VERSION ""

NS_ :

BS_:

BU_: HCU BMS MCU

BO_ 3221225472 VECTOR__INDEPENDENT_SIG_MSG: 0 Vector__XXX
 SG_ SI_30Bit : 0|30@1- (1,0) [0|0] "" Vector__XXX
 SG_ SI_29Bit : 0|29@1- (1,0) [0|0] "" Vector__XXX
 SG_ SI_28Bit : 0|28@1- (1,0) [0|0] "" Vector__XXX
 SG_ SI_27Bit : 0|27@1- (1,0) [0|0] "" Vector__XXX
 SG_ SI_26Bit : 0|26@1- (1,0) [0|0] "" Vector__XXX
 SG_ SI_25Bit : 0|25@1- (1,0) [0|0] "" Vector__XXX
 SG_ SI_23Bit : 0|23@1- (1,0) [0|0] "" Vector__XXX
 SG_ SI_22Bit : 0|22@1- (1,0) [0|0] "" Vector__XXX
 SG_ SI_21Bit : 0|21@1- (1,0) [0|0] "" Vector__XXX
 SG_ SI_20Bit : 0|20@1- (1,0) [0|0] "" Vector__XXX
 SG_ SI_19Bit : 0|19@1- (1,0) [0|0] "" Vector__XXX
 SG_ SI_18Bit : 0|18@1- (1,0) [0|0] "" Vector__XXX
 SG_ SI_17Bit : 0|17@1- (1,0) [0|0] "" Vector__XXX
 SG_ SI_15Bit : 0|15@1- (1,0) [0|0] "" Vector__XXX
 SG_ SI_14Bit : 0|14@1- (1,0) [0|0] "" Vector__XXX
 SG_ SI_13Bit : 0|13@1- (1,0) [0|0] "" Vector__XXX
 SG_ SI_11Bit : 0|11@1- (1,0) [0|0] "" Vector__XXX
 SG_ SI_10Bit : 0|10@1- (1,0) [0|0] "" Vector__XXX
 SG_ SI_09Bit : 0|9@1- (1,0) [0|0] "" Vector__XXX
 SG_ SI_07Bit : 0|7@1- (1,0) [0|0] "" Vector__XXX
 SG_ SI_06Bit : 0|6@1- (1,0) [0|0] "" Vector__XXX
 SG_ SI_05Bit : 0|5@1- (1,0) [0|0] "" Vector__XXX
 SG_ SI_03Bit : 0|3@1- (1,0) [0|0] "" Vector__XXX
 SG_ SI_02Bit : 0|2@1- (1,0) [0|0] "" Vector__XXX
 SG_ UI_30Bit : 0|30@1+ (1,0) [0|0] "" Vector__XXX
 SG_ UI_29Bit : 0|29@1+ (1,0) [0|0] "" Vector__XXX
 SG_ UI_28Bit : 0|28@1+ (1,0) [0|0] "" Vector__XXX
 SG_ UI_27Bit : 0|27@1+ (1,0) [0|0] "" Vector__XXX
 SG_ UI_26Bit : 0|26@1+ (1,0) [0|0] "" Vector__XXX
 SG_ UI_25Bit : 0|25@1+ (1,0) [0|0] "" Vector__XXX
 SG_ UI_23Bit : 0|23@1+ (1,0) [0|0] "" Vector__XXX
 SG_ UI_22Bit : 0|22@1+ (1,0) [0|0] "" Vector__XXX
 SG_ UI_21Bit : 0|21@1+ (1,0) [0|0] "" Vector__XXX
 SG_ UI_20Bit : 0|20@1+ (1,0) [0|0] "" Vector__XXX
 SG_ UI_19Bit : 0|19@1+ (1,0) [0|0] "" Vector__XXX
 SG_ UI_18Bit : 0|18@1+ (1,0) [0|0] "" Vector__XXX
 SG_ UI_17Bit : 0|17@1+ (1,0) [0|0] "" Vector__XXX
 SG_ UI_15Bit : 0|15@1+ (1,0) [0|0] "" Vector__XXX
 SG_ UI_14Bit : 0|14@1+ (1,0) [0|0] "" Vector__XXX
 SG_ UI_13Bit : 0|13@1+ (1,0) [0|0] "" Vector__XXX
 SG_ UI_11Bit : 0|11@1+ (1,0) [0|0] "" Vector__XXX
 SG_ UI_10Bit : 0|10@1+ (1,0) [0|0] "" Vector__XXX
 SG_ UI_09Bit : 0|9@1+ (1,0) [0|0] "" Vector__XXX
 SG_ UI_07Bit : 0|7@1+ (1,0) [0|0] "" Vector__XXX
 SG_ UI_06Bit : 0|6@1+ (1,0) [0|0] "" Vector__XXX
 SG_ UI_05Bit : 0|5@1+ (1,0) [0|0] "" Vector__XXX
 SG_ UI_03Bit : 0|3@1+ (1,0) [0|0] "" Vector__XXX
 SG_ UI_02Bit : 0|2@1+ (1,0) [0|0] "" Vector__XXX
 SG_ UI_12Bit : 0|12@1+ (1,0) [0|0] "" Vector__XXX
 SG_ UI_24Bit : 0|24@1+ (1,0) [0|0] "" Vector__XXX
 SG_ UI_01Bit : 0|1@1+ (1,0) [0|0] "" Vector__XXX
 SG_ SI_04Bit : 0|4@1- (1,0) [0|0] "" Vector__XXX
 SG_ SI_16Bit : 0|16@1- (1,0) [0|0] "" Vector__XXX
 SG_ SI_32Bit : 0|32@1- (1,0) [0|0] "" Vector__XXX
 SG_ SI_08Bit : 0|8@1- (1,0) [0|0] "" Vector__XXX
 SG_ SI_24Bit : 0|24@1- (1,0) [0|0] "" Vector__XXX
 SG_ UI_04Bit : 0|4@1+ (1,0) [0|0] "" Vector__XXX
 SG_ UI_32Bit : 0|32@1+ (1,0) [0|0] "" Vector__XXX
 SG_ UI_16Bit : 0|16@1+ (1,0) [0|0] "" Vector__XXX
 SG_ UI_08Bit : 0|8@1+ (1,0) [0|0] "" Vector__XXX
 SG_ UI_31Bit : 0|31@1+ (1,0) [0|0] "" Vector__XXX
 SG_ SI_12Bit : 0|12@1- (1,0) [0|0] "" Vector__XXX
 SG_ SI_31Bit : 0|31@1- (1,0) [0|0] "" Vector__XXX

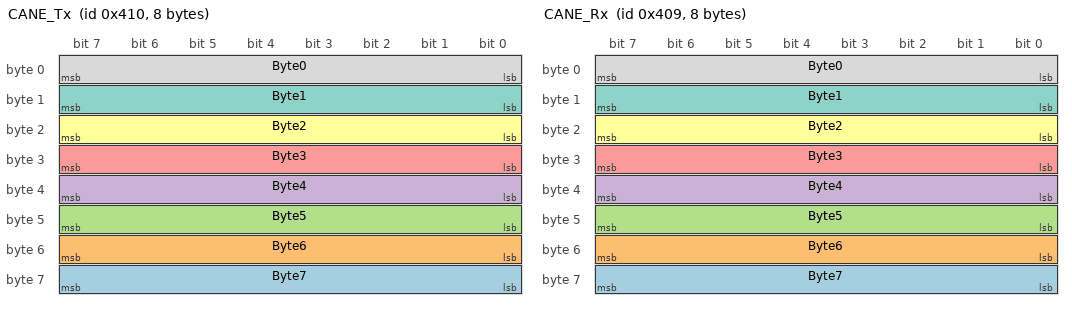
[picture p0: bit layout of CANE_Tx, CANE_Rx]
BO_ 1040 CANE_Tx: 8 Vector__XXX
 SG_ Byte7 : 56|8@1+ (1,0) [0|0] "" Vector__XXX
 SG_ Byte6 : 48|8@1+ (1,0) [0|0] "" Vector__XXX
 SG_ Byte5 : 40|8@1+ (1,0) [0|0] "" Vector__XXX
 SG_ Byte4 : 32|8@1+ (1,0) [0|0] "" Vector__XXX
 SG_ Byte3 : 24|8@1+ (1,0) [0|0] "" Vector__XXX
 SG_ Byte2 : 16|8@1+ (1,0) [0|0] "" Vector__XXX
 SG_ Byte1 : 8|8@1+ (1,0) [0|0] "" Vector__XXX
 SG_ Byte0 : 0|8@1+ (1,0) [0|0] "" Vector__XXX

BO_ 1033 CANE_Rx: 8 Vector__XXX
 SG_ Byte7 : 56|8@1+ (1,0) [0|0] "" Vector__XXX
 SG_ Byte6 : 48|8@1+ (1,0) [0|0] "" Vector__XXX
 SG_ Byte5 : 40|8@1+ (1,0) [0|0] "" Vector__XXX
 SG_ Byte4 : 32|8@1+ (1,0) [0|0] "" Vector__XXX
 SG_ Byte3 : 24|8@1+ (1,0) [0|0] "" Vector__XXX
 SG_ Byte2 : 16|8@1+ (1,0) [0|0] "" Vector__XXX
 SG_ Byte1 : 8|8@1+ (1,0) [0|0] "" Vector__XXX
 SG_ Byte0 : 0|8@1+ (1,0) [0|0] "" Vector__XXX

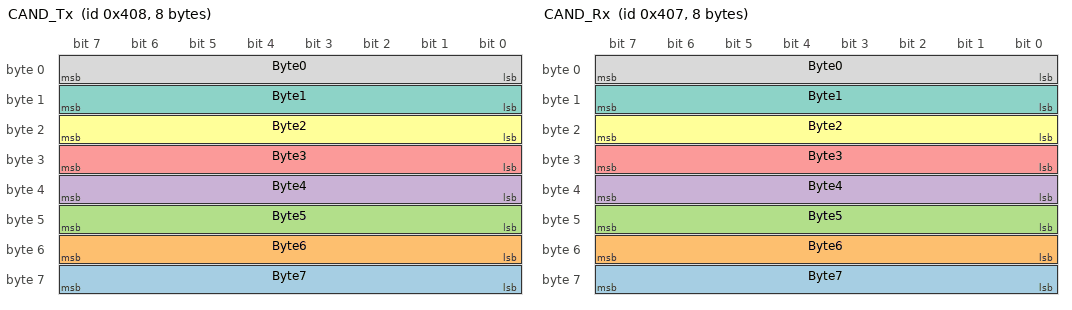
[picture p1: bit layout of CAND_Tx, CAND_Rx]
BO_ 1032 CAND_Tx: 8 Vector__XXX
 SG_ Byte7 : 56|8@1+ (1,0) [0|0] "" Vector__XXX
 SG_ Byte6 : 48|8@1+ (1,0) [0|0] "" Vector__XXX
 SG_ Byte5 : 40|8@1+ (1,0) [0|0] "" Vector__XXX
 SG_ Byte4 : 32|8@1+ (1,0) [0|0] "" Vector__XXX
 SG_ Byte3 : 24|8@1+ (1,0) [0|0] "" Vector__XXX
 SG_ Byte2 : 16|8@1+ (1,0) [0|0] "" Vector__XXX
 SG_ Byte1 : 8|8@1+ (1,0) [0|0] "" Vector__XXX
 SG_ Byte0 : 0|8@1+ (1,0) [0|0] "" Vector__XXX

BO_ 1031 CAND_Rx: 8 Vector__XXX
 SG_ Byte7 : 56|8@1+ (1,0) [0|0] "" Vector__XXX
 SG_ Byte6 : 48|8@1+ (1,0) [0|0] "" Vector__XXX
 SG_ Byte5 : 40|8@1+ (1,0) [0|0] "" Vector__XXX
 SG_ Byte4 : 32|8@1+ (1,0) [0|0] "" Vector__XXX
 SG_ Byte3 : 24|8@1+ (1,0) [0|0] "" Vector__XXX
 SG_ Byte2 : 16|8@1+ (1,0) [0|0] "" Vector__XXX
 SG_ Byte1 : 8|8@1+ (1,0) [0|0] "" Vector__XXX
 SG_ Byte0 : 0|8@1+ (1,0) [0|0] "" Vector__XXX

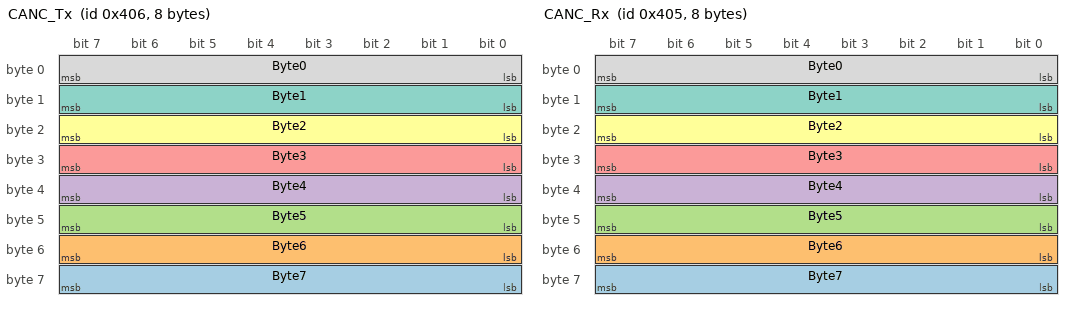
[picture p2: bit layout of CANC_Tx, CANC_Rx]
BO_ 1030 CANC_Tx: 8 Vector__XXX
 SG_ Byte7 : 56|8@1+ (1,0) [0|0] "" Vector__XXX
 SG_ Byte6 : 48|8@1+ (1,0) [0|0] "" Vector__XXX
 SG_ Byte5 : 40|8@1+ (1,0) [0|0] "" Vector__XXX
 SG_ Byte4 : 32|8@1+ (1,0) [0|0] "" Vector__XXX
 SG_ Byte3 : 24|8@1+ (1,0) [0|0] "" Vector__XXX
 SG_ Byte2 : 16|8@1+ (1,0) [0|0] "" Vector__XXX
 SG_ Byte1 : 8|8@1+ (1,0) [0|0] "" Vector__XXX
 SG_ Byte0 : 0|8@1+ (1,0) [0|0] "" Vector__XXX

BO_ 1029 CANC_Rx: 8 Vector__XXX
 SG_ Byte7 : 56|8@1+ (1,0) [0|0] "" Vector__XXX
 SG_ Byte6 : 48|8@1+ (1,0) [0|0] "" Vector__XXX
 SG_ Byte5 : 40|8@1+ (1,0) [0|0] "" Vector__XXX
 SG_ Byte4 : 32|8@1+ (1,0) [0|0] "" Vector__XXX
 SG_ Byte3 : 24|8@1+ (1,0) [0|0] "" Vector__XXX
 SG_ Byte2 : 16|8@1+ (1,0) [0|0] "" Vector__XXX
 SG_ Byte1 : 8|8@1+ (1,0) [0|0] "" Vector__XXX
 SG_ Byte0 : 0|8@1+ (1,0) [0|0] "" Vector__XXX

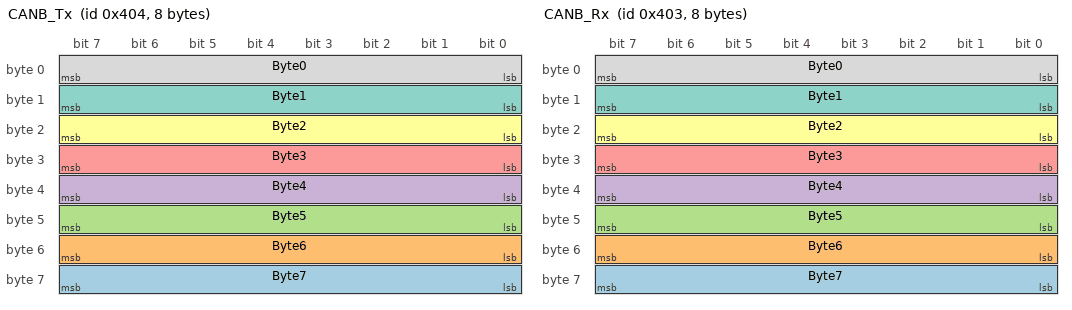
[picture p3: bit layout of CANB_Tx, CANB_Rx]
BO_ 1028 CANB_Tx: 8 Vector__XXX
 SG_ Byte7 : 56|8@1+ (1,0) [0|0] "" Vector__XXX
 SG_ Byte6 : 48|8@1+ (1,0) [0|0] "" Vector__XXX
 SG_ Byte5 : 40|8@1+ (1,0) [0|0] "" Vector__XXX
 SG_ Byte4 : 32|8@1+ (1,0) [0|0] "" Vector__XXX
 SG_ Byte3 : 24|8@1+ (1,0) [0|0] "" Vector__XXX
 SG_ Byte2 : 16|8@1+ (1,0) [0|0] "" Vector__XXX
 SG_ Byte1 : 8|8@1+ (1,0) [0|0] "" Vector__XXX
 SG_ Byte0 : 0|8@1+ (1,0) [0|0] "" Vector__XXX

BO_ 1027 CANB_Rx: 8 Vector__XXX
 SG_ Byte7 : 56|8@1+ (1,0) [0|0] "" Vector__XXX
 SG_ Byte6 : 48|8@1+ (1,0) [0|0] "" Vector__XXX
 SG_ Byte5 : 40|8@1+ (1,0) [0|0] "" Vector__XXX
 SG_ Byte4 : 32|8@1+ (1,0) [0|0] "" Vector__XXX
 SG_ Byte3 : 24|8@1+ (1,0) [0|0] "" Vector__XXX
 SG_ Byte2 : 16|8@1+ (1,0) [0|0] "" Vector__XXX
 SG_ Byte1 : 8|8@1+ (1,0) [0|0] "" Vector__XXX
 SG_ Byte0 : 0|8@1+ (1,0) [0|0] "" Vector__XXX

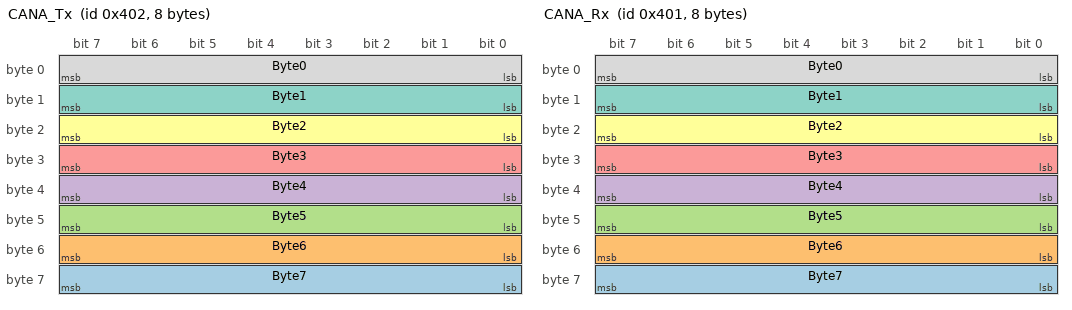
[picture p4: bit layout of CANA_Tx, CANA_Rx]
BO_ 1026 CANA_Tx: 8 Vector__XXX
 SG_ Byte7 : 56|8@1+ (1,0) [0|0] "" Vector__XXX
 SG_ Byte6 : 48|8@1+ (1,0) [0|0] "" Vector__XXX
 SG_ Byte5 : 40|8@1+ (1,0) [0|0] "" Vector__XXX
 SG_ Byte4 : 32|8@1+ (1,0) [0|0] "" Vector__XXX
 SG_ Byte3 : 24|8@1+ (1,0) [0|0] "" Vector__XXX
 SG_ Byte2 : 16|8@1+ (1,0) [0|0] "" Vector__XXX
 SG_ Byte1 : 8|8@1+ (1,0) [0|0] "" Vector__XXX
 SG_ Byte0 : 0|8@1+ (1,0) [0|0] "" Vector__XXX

BO_ 1025 CANA_Rx: 8 Vector__XXX
 SG_ Byte7 : 56|8@1+ (1,0) [0|0] "" Vector__XXX
 SG_ Byte6 : 48|8@1+ (1,0) [0|0] "" Vector__XXX
 SG_ Byte5 : 40|8@1+ (1,0) [0|0] "" Vector__XXX
 SG_ Byte4 : 32|8@1+ (1,0) [0|0] "" Vector__XXX
 SG_ Byte3 : 24|8@1+ (1,0) [0|0] "" Vector__XXX
 SG_ Byte2 : 16|8@1+ (1,0) [0|0] "" Vector__XXX
 SG_ Byte1 : 8|8@1+ (1,0) [0|0] "" Vector__XXX
 SG_ Byte0 : 0|8@1+ (1,0) [0|0] "" Vector__XXX

BO_ 520 M_UI09: 8 Vector__XXX
 SG_ UI_16Bit : 0|16@1+ (1,0) [0|0] "" Vector__XXX

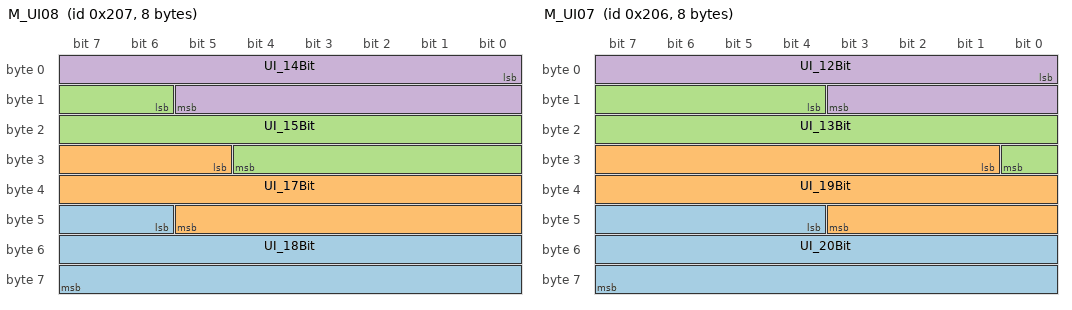
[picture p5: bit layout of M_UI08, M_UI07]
BO_ 519 M_UI08: 8 Vector__XXX
 SG_ UI_18Bit : 46|18@1+ (1,0) [0|0] "" Vector__XXX
 SG_ UI_17Bit : 29|17@1+ (1,0) [0|0] "" Vector__XXX
 SG_ UI_15Bit : 14|15@1+ (1,0) [0|0] "" Vector__XXX
 SG_ UI_14Bit : 0|14@1+ (1,0) [0|0] "" Vector__XXX

BO_ 518 M_UI07: 8 Vector__XXX
 SG_ UI_20Bit : 44|20@1+ (1,0) [0|0] "" Vector__XXX
 SG_ UI_19Bit : 25|19@1+ (1,0) [0|0] "" Vector__XXX
 SG_ UI_13Bit : 12|13@1+ (1,0) [0|0] "" Vector__XXX
 SG_ UI_12Bit : 0|12@1+ (1,0) [0|0] "" Vector__XXX

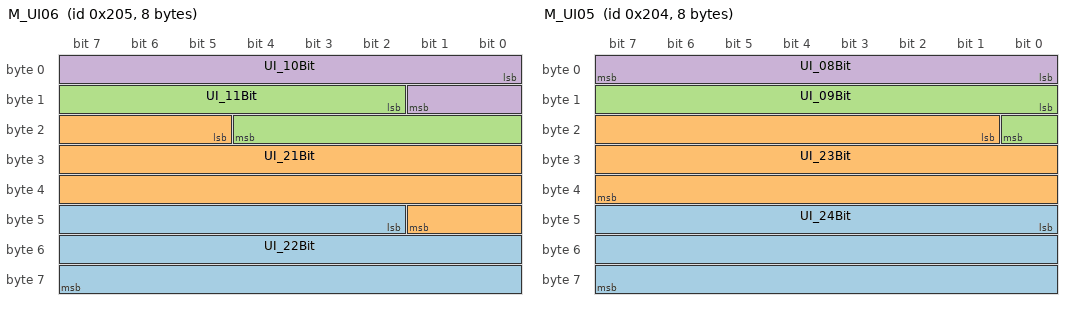
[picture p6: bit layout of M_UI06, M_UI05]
BO_ 517 M_UI06: 8 Vector__XXX
 SG_ UI_22Bit : 42|22@1+ (1,0) [0|0] "" Vector__XXX
 SG_ UI_21Bit : 21|21@1+ (1,0) [0|0] "" Vector__XXX
 SG_ UI_11Bit : 10|11@1+ (1,0) [0|0] "" Vector__XXX
 SG_ UI_10Bit : 0|10@1+ (1,0) [0|0] "" Vector__XXX

BO_ 516 M_UI05: 8 Vector__XXX
 SG_ UI_24Bit : 40|24@1+ (1,0) [0|0] "" Vector__XXX
 SG_ UI_23Bit : 17|23@1+ (1,0) [0|0] "" Vector__XXX
 SG_ UI_09Bit : 8|9@1+ (1,0) [0|0] "" Vector__XXX
 SG_ UI_08Bit : 0|8@1+ (1,0) [0|0] "" Vector__XXX

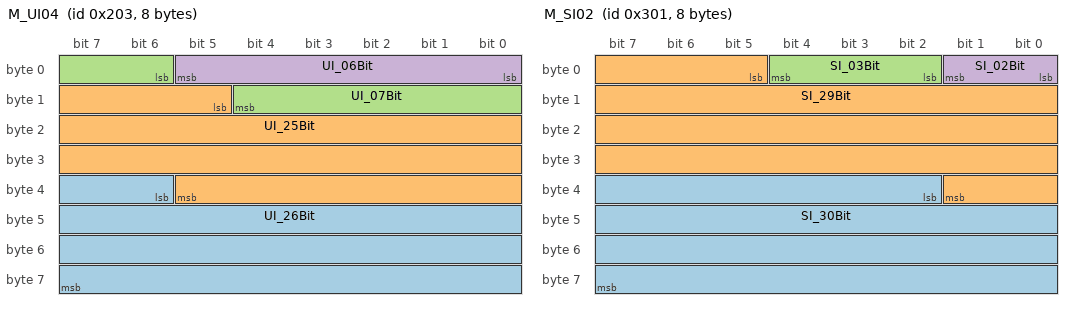
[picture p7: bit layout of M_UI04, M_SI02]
BO_ 515 M_UI04: 8 Vector__XXX
 SG_ UI_26Bit : 38|26@1+ (1,0) [0|0] "" Vector__XXX
 SG_ UI_25Bit : 13|25@1+ (1,0) [0|0] "" Vector__XXX
 SG_ UI_07Bit : 6|7@1+ (1,0) [0|0] "" Vector__XXX
 SG_ UI_06Bit : 0|6@1+ (1,0) [0|0] "" Vector__XXX

BO_ 769 M_SI02: 8 Vector__XXX
 SG_ SI_30Bit : 34|30@1- (1,0) [0|0] "" Vector__XXX
 SG_ SI_29Bit : 5|29@1- (1,0) [0|0] "" Vector__XXX
 SG_ SI_03Bit : 2|3@1- (1,0) [0|0] "" Vector__XXX
 SG_ SI_02Bit : 0|2@1- (1,0) [0|0] "" Vector__XXX

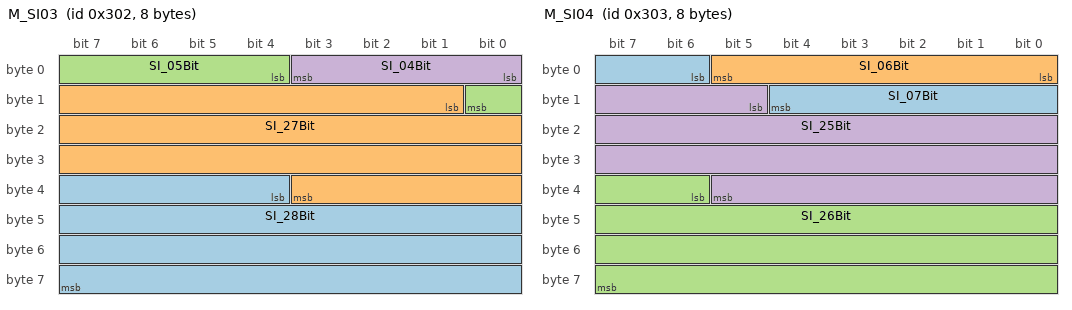
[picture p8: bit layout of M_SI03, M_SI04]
BO_ 770 M_SI03: 8 Vector__XXX
 SG_ SI_28Bit : 36|28@1- (1,0) [0|0] "" Vector__XXX
 SG_ SI_27Bit : 9|27@1- (1,0) [0|0] "" Vector__XXX
 SG_ SI_05Bit : 4|5@1- (1,0) [0|0] "" Vector__XXX
 SG_ SI_04Bit : 0|4@1- (1,0) [0|0] "" Vector__XXX

BO_ 771 M_SI04: 8 Vector__XXX
 SG_ SI_07Bit : 6|7@1- (1,0) [0|0] "" Vector__XXX
 SG_ SI_06Bit : 0|6@1- (1,0) [0|0] "" Vector__XXX
 SG_ SI_26Bit : 38|26@1- (1,0) [0|0] "" Vector__XXX
 SG_ SI_25Bit : 13|25@1- (1,0) [0|0] "" Vector__XXX

BO_ 776 M_SI09: 8 Vector__XXX
 SG_ SI_16Bit : 0|16@1- (1,0) [0|0] "" Vector__XXX

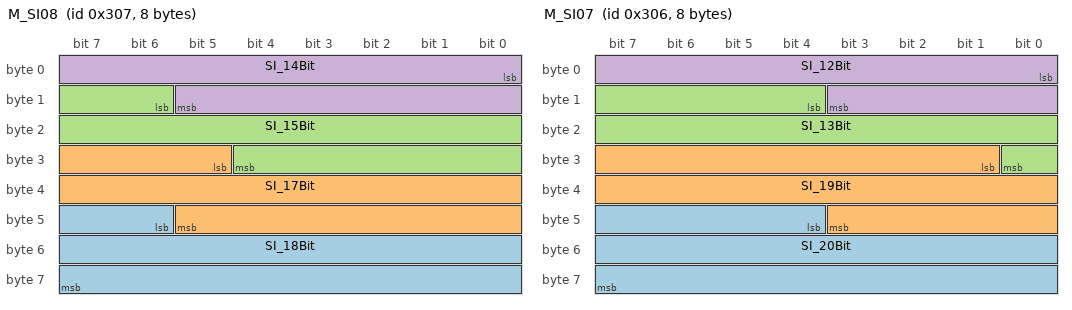
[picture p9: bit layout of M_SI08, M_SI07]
BO_ 775 M_SI08: 8 Vector__XXX
 SG_ SI_18Bit : 46|18@1- (1,0) [0|0] "" Vector__XXX
 SG_ SI_17Bit : 29|17@1- (1,0) [0|0] "" Vector__XXX
 SG_ SI_15Bit : 14|15@1- (1,0) [0|0] "" Vector__XXX
 SG_ SI_14Bit : 0|14@1- (1,0) [0|0] "" Vector__XXX

BO_ 774 M_SI07: 8 Vector__XXX
 SG_ SI_20Bit : 44|20@1- (1,0) [0|0] "" Vector__XXX
 SG_ SI_19Bit : 25|19@1- (1,0) [0|0] "" Vector__XXX
 SG_ SI_13Bit : 12|13@1- (1,0) [0|0] "" Vector__XXX
 SG_ SI_12Bit : 0|12@1- (1,0) [0|0] "" Vector__XXX

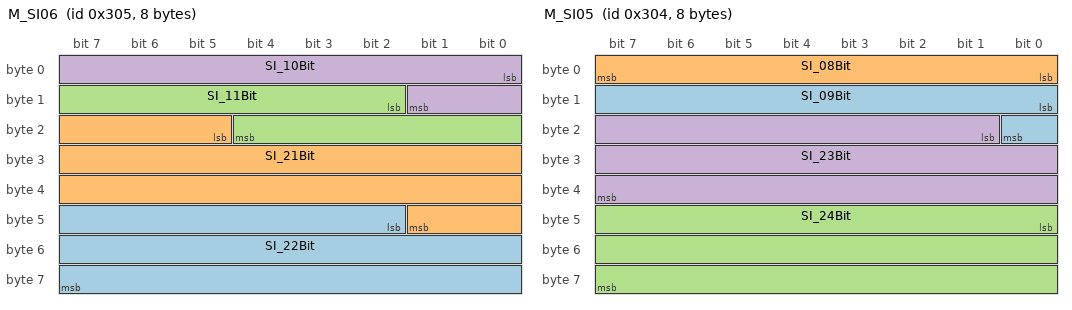
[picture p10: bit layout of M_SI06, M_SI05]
BO_ 773 M_SI06: 8 Vector__XXX
 SG_ SI_22Bit : 42|22@1- (1,0) [0|0] "" Vector__XXX
 SG_ SI_21Bit : 21|21@1- (1,0) [0|0] "" Vector__XXX
 SG_ SI_11Bit : 10|11@1- (1,0) [0|0] "" Vector__XXX
 SG_ SI_10Bit : 0|10@1- (1,0) [0|0] "" Vector__XXX

BO_ 772 M_SI05: 8 Vector__XXX
 SG_ SI_09Bit : 8|9@1- (1,0) [0|0] "" Vector__XXX
 SG_ SI_08Bit : 0|8@1- (1,0) [0|0] "" Vector__XXX
 SG_ SI_24Bit : 40|24@1- (1,0) [0|0] "" Vector__XXX
 SG_ SI_23Bit : 17|23@1- (1,0) [0|0] "" Vector__XXX

BO_ 768 M_SI01: 8 Vector__XXX
 SG_ SI_32Bit : 31|32@1- (1,0) [0|0] "" Vector__XXX
 SG_ SI_31Bit : 0|31@1- (1,0) [0|0] "" Vector__XXX

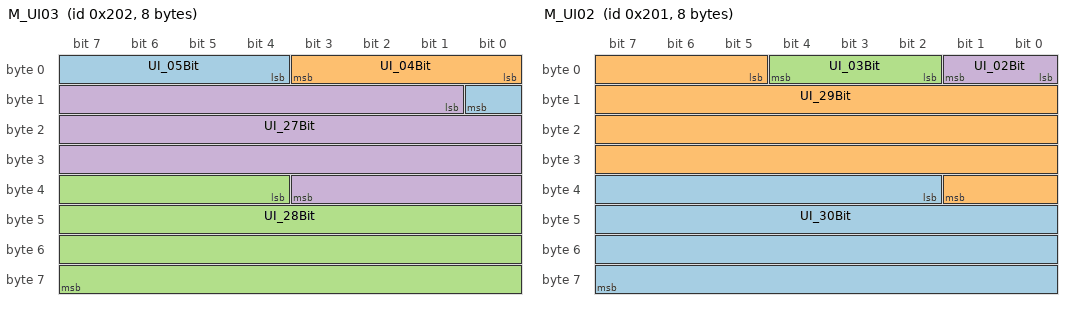
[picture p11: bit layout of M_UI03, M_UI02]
BO_ 514 M_UI03: 8 Vector__XXX
 SG_ UI_05Bit : 4|5@1+ (1,0) [0|0] "" Vector__XXX
 SG_ UI_04Bit : 0|4@1+ (1,0) [0|0] "" Vector__XXX
 SG_ UI_28Bit : 36|28@1+ (1,0) [0|0] "" Vector__XXX
 SG_ UI_27Bit : 9|27@1+ (1,0) [0|0] "" Vector__XXX

BO_ 513 M_UI02: 8 Vector__XXX
 SG_ UI_30Bit : 34|30@1+ (1,0) [0|0] "" Vector__XXX
 SG_ UI_29Bit : 5|29@1+ (1,0) [0|0] "" Vector__XXX
 SG_ UI_03Bit : 2|3@1+ (1,0) [0|0] "" Vector__XXX
 SG_ UI_02Bit : 0|2@1+ (1,0) [0|0] "" Vector__XXX

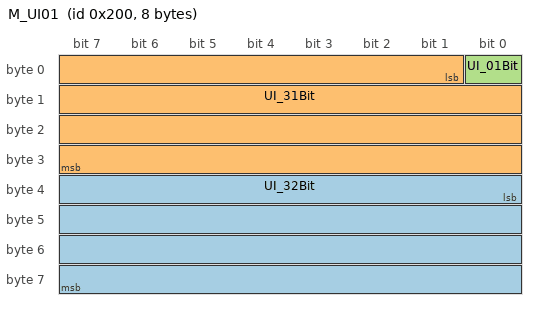
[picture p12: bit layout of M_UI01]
BO_ 512 M_UI01: 8 Vector__XXX
 SG_ UI_32Bit : 32|32@1+ (1,0) [0|0] "" Vector__XXX
 SG_ UI_31Bit : 1|31@1+ (1,0) [0|0] "" Vector__XXX
 SG_ UI_01Bit : 0|1@1+ (1,0) [0|0] "" Vector__XXX

CM_ BO_ 3221225472 "This is a message for not used signals, created by Vector CANdb++ DBC OLE DB Provider.";
BA_DEF_ SG_  "GenSigEnvVarType" ENUM  "int","float","undef";
BA_DEF_ SG_  "GenSigSendType" ENUM  "Cyclic","OnWrite","OnWriteWithRepetition","OnChange","OnChangeWithRepetition","IfActive","IfActiveWithRepetition";
BA_DEF_ BO_  "GenMsgDelayTime" INT 1 1000;
BA_DEF_ BO_  "GenMsgCycleTime" INT 2 50000;
BA_DEF_ BO_  "GenMsgCycleTimeFast" INT 2 100000;
BA_DEF_ BO_  "GenMsgILSupport" ENUM  "No","Yes";
BA_DEF_ BU_  "TpNodeBaseAddress" HEX 0 33554431;
BA_DEF_ BU_  "TpUseFC" INT 0 1;
BA_DEF_ BU_  "TpCanBus" INT 1 2;
BA_DEF_ BU_  "TpRxMask" HEX 0 65535;
BA_DEF_ BU_  "TpRxIdentifier" HEX 0 536870911;
BA_DEF_ BU_  "TpTxIdentifier" HEX 0 536870911;
BA_DEF_ BU_  "ILUsed" ENUM  "Yes","No";
BA_DEF_ BU_  "TpAddressingMode" INT 0 3;
BA_DEF_  "GenNWMTalkNM" STRING ;
BA_DEF_  "GenNWMGotoMode_BusSleep" STRING ;
BA_DEF_  "GenNWMGotoMode_Awake" STRING ;
BA_DEF_  "GenNWMApCanSleep" STRING ;
BA_DEF_  "GenNWMApCanOn" STRING ;
BA_DEF_  "GenNWMApCanOff" STRING ;
BA_DEF_  "NmBaseAddress" HEX 1024 1055;
BA_DEF_  "GenEnvVarPrefix" STRING ;
BA_DEF_  "GenEnvVarEndingSnd" STRING ;
BA_DEF_  "GenEnvVarEndingDsp" STRING ;
BA_DEF_  "DBName" STRING ;
BA_DEF_DEF_  "GenSigEnvVarType" "undef";
BA_DEF_DEF_  "GenSigSendType" "Cyclic";
BA_DEF_DEF_  "GenMsgDelayTime" 1;
BA_DEF_DEF_  "GenMsgCycleTime" 2;
BA_DEF_DEF_  "GenMsgCycleTimeFast" 100;
BA_DEF_DEF_  "GenMsgILSupport" "Yes";
BA_DEF_DEF_  "TpNodeBaseAddress" 1536;
BA_DEF_DEF_  "TpUseFC" 1;
BA_DEF_DEF_  "TpCanBus" 1;
BA_DEF_DEF_  "TpRxMask" 255;
BA_DEF_DEF_  "TpRxIdentifier" 1;
BA_DEF_DEF_  "TpTxIdentifier" 1;
BA_DEF_DEF_  "ILUsed" "Yes";
BA_DEF_DEF_  "TpAddressingMode" 1;
BA_DEF_DEF_  "GenNWMTalkNM" "TalkNM()";
BA_DEF_DEF_  "GenNWMGotoMode_BusSleep" "GotoMode_BusSleep()";
BA_DEF_DEF_  "GenNWMGotoMode_Awake" "GotoMode_Awake()";
BA_DEF_DEF_  "GenNWMApCanSleep" "apCanSleep()";
BA_DEF_DEF_  "GenNWMApCanOn" "apCanOn()";
BA_DEF_DEF_  "GenNWMApCanOff" "apCanOff()";
BA_DEF_DEF_  "NmBaseAddress" 1024;
BA_DEF_DEF_  "GenEnvVarPrefix" "Env";
BA_DEF_DEF_  "GenEnvVarEndingSnd" "_";
BA_DEF_DEF_  "GenEnvVarEndingDsp" "Dsp_";
BA_DEF_DEF_  "DBName" "";
BA_ "DBName" "TAF_CAN";
